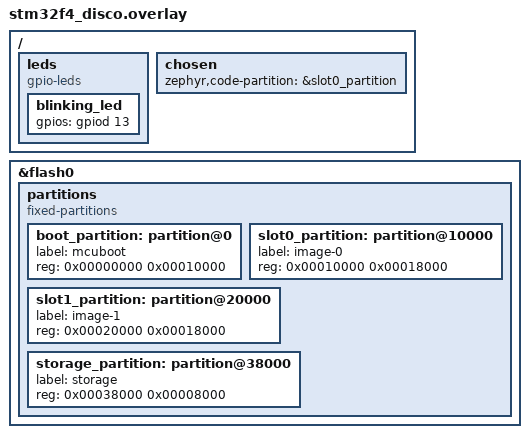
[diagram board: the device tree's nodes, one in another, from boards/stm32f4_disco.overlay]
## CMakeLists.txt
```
cmake_minimum_required(VERSION 3.22)
set(CMAKE_EXPORT_COMPILE_COMMANDS ON)
set(BOARD stm32f4_disco )

find_package(Zephyr REQUIRED HINTS $ENV{ZEPHYR_BASE})
project(006_bootloader_f407disco)

target_sources(app PRIVATE src/main.c)
```

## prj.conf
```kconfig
CONFIG_MAIN_THREAD_PRIORITY=0
CONFIG_MAIN_STACK_SIZE=1024
CONFIG_SYSTEM_WORKQUEUE_STACK_SIZE=1024
CONFIG_LOG=y
CONFIG_SERIAL=y
CONFIG_GPIO=y

CONFIG_PRINTK=y
CONFIG_LOG_PRINTK=y

CONFIG_BOOTLOADER_MCUBOOT=y

CONFIG_MCUBOOT_SIGNATURE_KEY_FILE="bootloader/mcuboot/mykey-ecdsa-p256.pem"
CONFIG_MCUBOOT_ENCRYPTION_KEY_FILE="bootloader/mcuboot/mykey-ecdsa-p256.pem"
```

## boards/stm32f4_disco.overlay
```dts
/ {
    leds {
        status = "okay";
        compatible = "gpio-leds"; 
        blinking_led: blinking_led { //yorum
            status = "okay";
            gpios = <&gpiod 13 GPIO_ACTIVE_HIGH>;  // GPIO_ACTIVE_HIGH (or GPIO_ACTIVE_LOW): Specifies the active logic level of a GPIO pin.
        };
    };
};

&flash0 {
    partitions {
        compatible = "fixed-partitions";
        #address-cells = <1>;
        #size-cells = <1>;

        boot_partition: partition@0 {
            label = "mcuboot";
            reg = <0x00000000 0x00010000>; /* 64 KB */
        };

        slot0_partition: partition@10000 {
            label = "image-0";
            reg = <0x00010000 0x00018000>; /* 96 KB */
        };

        slot1_partition: partition@20000 {
            label = "image-1";
            reg = <0x00020000 0x00018000>; /* 96 KB */
        };

        storage_partition: partition@38000 {
            label = "storage";
            reg = <0x00038000 0x00008000>; /* 32 KB */
        };
    };
};

/ {
    chosen {
        zephyr,code-partition = &slot0_partition;
    };
};
```

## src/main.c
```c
#include <stdio.h>
#include <zephyr/kernel.h>
#include <zephyr/drivers/gpio.h>
#include <zephyr/devicetree.h>

#define GPIO_PIN 13
#define LED0_NODE DT_NODELABEL(blinking_led)
int counter = 30;
//#if DT_NODE_HAS_STATUS(MY_SERIAL, okay)
static const struct gpio_dt_spec led = GPIO_DT_SPEC_GET(LED0_NODE, gpios);
//#else
//#error "Node is disabled"
//#endif

void increment_counter(void);
int main(void){
    if (!device_is_ready(led.port)) {
        //printk("GPIO device %s is not ready\n", gpio_ct_dev->name);
        return 1;
    }
    int gpio_conf;
    //gpio_conf = gpio_pin_configure(led.port,led.pin, led.dt_flags);
    gpio_conf = gpio_pin_configure_dt(&led, GPIO_OUTPUT_ACTIVE);
    //GPIO_OUTPUT_ACTIVE (or GPIO_OUTPUT_INACTIVE): Configures a GPIO pin
    // as an output and sets its initial state to the active (or inactive) state.
    counter = counter + 1;

    int pin_set = 0;
    while(true){
        increment_counter();
        //pin_set = gpio_pin_set_raw(led.port, led.pin, 1);
        //pin_set = gpio_pin_set_dt(&led, 1);
        pin_set = gpio_pin_toggle_dt(&led);
        k_msleep(1000); // Sleep for 1 second
        //pin_set = gpio_pin_set_dt(&led, 0);
        //k_msleep(1000); // Sleep for 1 second
    }
    return 0;
}
void increment_counter(){
    counter = counter + 1;
}
    
```

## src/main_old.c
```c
#include <zephyr/kernel.h>
#include <zephyr/drivers/gpio.h>

#define GPIO_PIN 13
int counter = 30;
static const struct device *gpio_ct_dev = DEVICE_DT_GET(DT_NODELABEL(gpiod));
void increment_counter(void);
int main(void){
    if (!device_is_ready(gpio_ct_dev)) {
        //printk("GPIO device %s is not ready\n", gpio_ct_dev->name);
        return 1;
    }
    int gpio_conf;
    gpio_conf = gpio_pin_configure(gpio_ct_dev,GPIO_PIN, GPIO_OUTPUT_ACTIVE);

    counter = counter + 1;

    int pin_set = 0;
    while(true){
        increment_counter();
        pin_set = gpio_pin_set_raw(gpio_ct_dev, GPIO_PIN, 1);
        //printk("Hello World\n");
        k_msleep(1000); // Sleep for 1 second
        pin_set = gpio_pin_set_raw(gpio_ct_dev, GPIO_PIN, 0);
        
        k_msleep(1000); // Sleep for 1 second
    }
    return 0;
}
void increment_counter(){
    counter = counter + 1;
}
    
```
